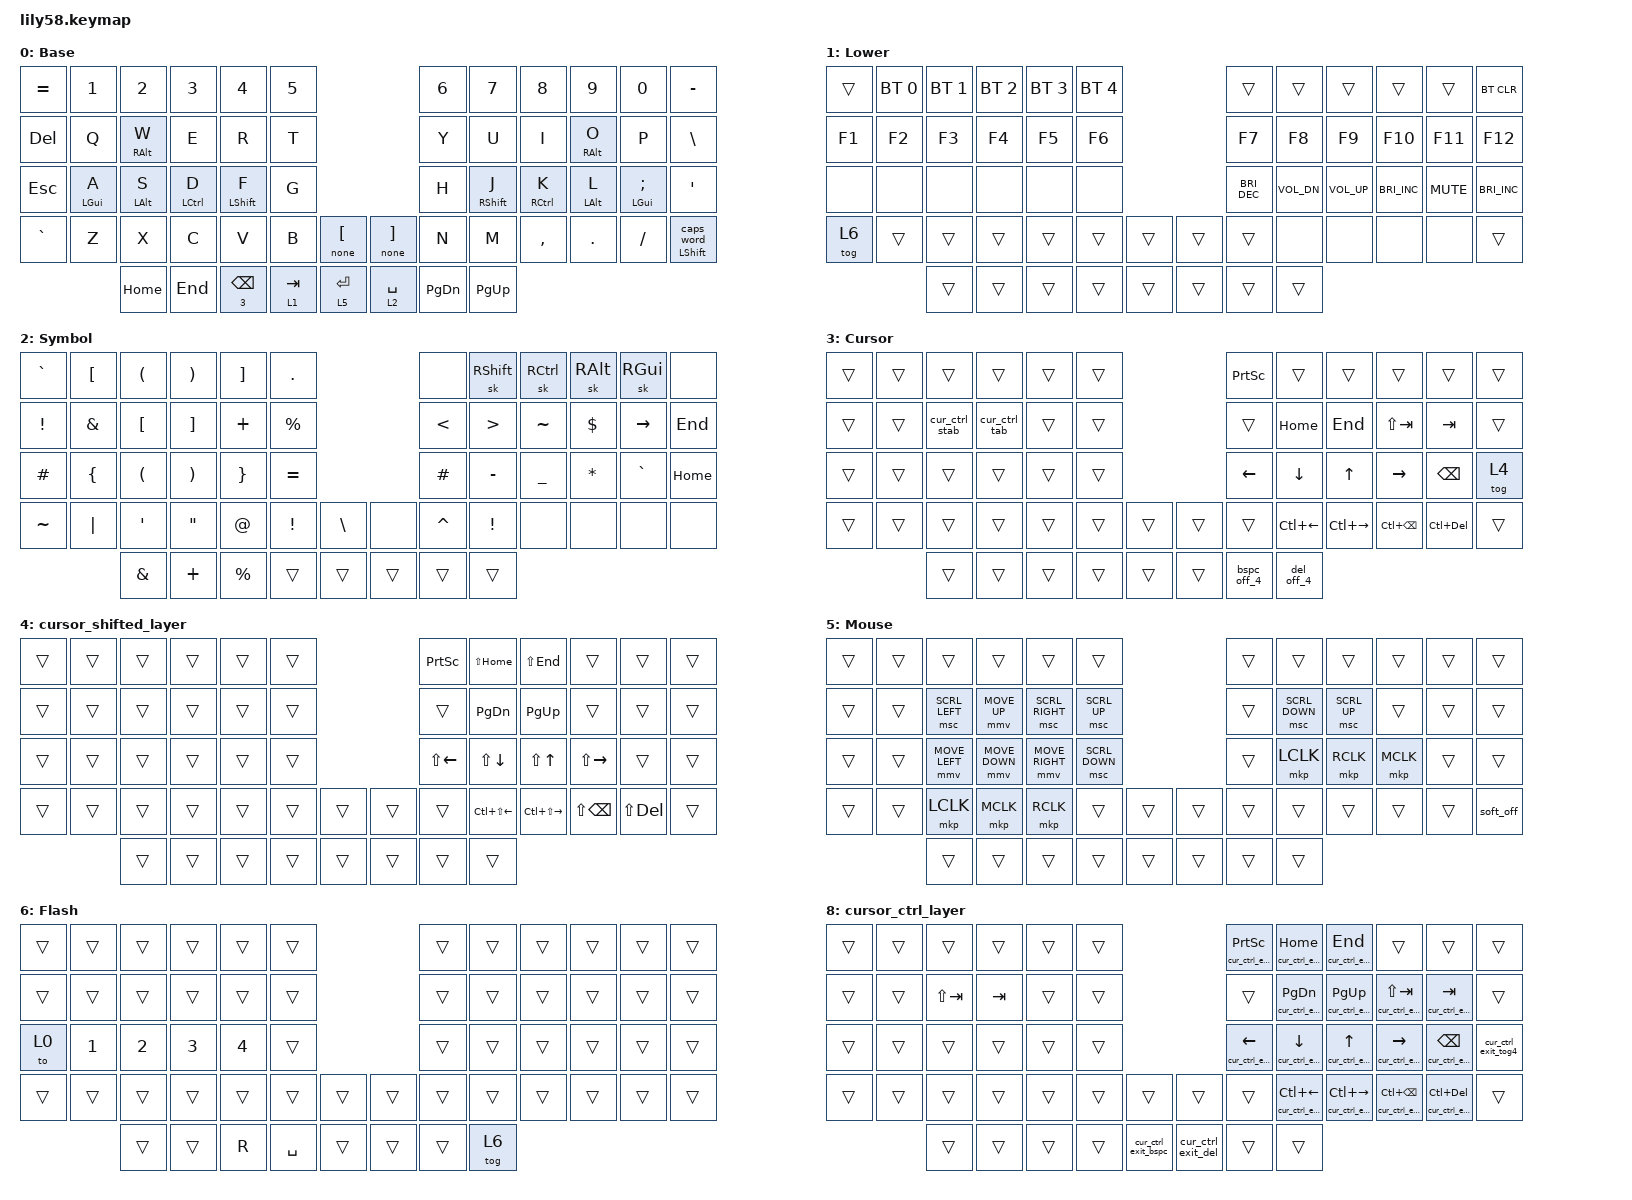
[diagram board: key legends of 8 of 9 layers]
/*
 * Copyright (c) 2020 The ZMK Contributors
 *
 * SPDX-License-Identifier: MIT
 */

#include <behaviors.dtsi>
#include <dt-bindings/zmk/keys.h>
#include <dt-bindings/zmk/bt.h>
#include <dt-bindings/zmk/ext_power.h>

#define ZMK_POINTING_DEFAULT_MOVE_VAL 2100  // default: 600
#define ZMK_POINTING_DEFAULT_SCRL_VAL 20    // default: 10
#include <dt-bindings/zmk/pointing.h>

#define LAYER_CtrlFlag 9
#define LAYER_CursorCtrl 10

/ {
    chosen {
        zmk,kscan = &sideband_scan;
    };
};

&mmv {
    x-input-code = <INPUT_REL_X>;
    y-input-code = <INPUT_REL_Y>;
    time-to-max-speed-ms = <700>;
    acceleration-exponent = <1>;
};

/ {
    macros {
        bspc_off_4: bspc_off_4 {
            compatible = "zmk,behavior-macro";
            wait-ms = <0>;
            #binding-cells = <0>;
            bindings = <&layer_off 4>, <&kp BSPC>;
        };

        del_off_4: del_off_4 {
            compatible = "zmk,behavior-macro";
            wait-ms = <0>;
            #binding-cells = <0>;
            bindings = <&layer_off 4>, <&kp DEL>;
        };

        mod_off_4: mod_off_4 {
            compatible = "zmk,behavior-macro-one-param";
            wait-ms = <0>;
            tap-ms = <0>;
            #binding-cells = <1>;
            bindings = <&macro_tap &layer_off 4>,
            <&macro_param_1to1>,
            <&macro_press &mo MACRO_PLACEHOLDER>,
            <&macro_pause_for_release>,
            <&kt_off LCTRL>,
            <&layer_off LAYER_CtrlFlag>,
            <&macro_param_1to1>,
            <&macro_release &mo MACRO_PLACEHOLDER>,
            <&macro_tap &layer_off 4>;
        };

        cur_ctrl_stab: cur_ctrl_stab {
            compatible = "zmk,behavior-macro";
            wait-ms = <0>;
            tap-ms = <0>;
            #binding-cells = <0>;
            bindings = <&kt_on LCTRL>, <&tog_on LAYER_CtrlFlag>, <&kp LS(TAB)>;
        };

        cur_ctrl_tab: cur_ctrl_tab {
            compatible = "zmk,behavior-macro";
            wait-ms = <0>;
            tap-ms = <0>;
            #binding-cells = <0>;
            bindings = <&kt_on LCTRL>, <&tog_on LAYER_CtrlFlag>, <&kp TAB>;
        };

        cur_ctrl_exit: cur_ctrl_exit {
            compatible = "zmk,behavior-macro-one-param";
            wait-ms = <0>;
            tap-ms = <0>;
            #binding-cells = <1>;
            bindings = <&kt_off LCTRL>,
                       <&layer_off LAYER_CtrlFlag>,
                       <&macro_param_1to1>,
                       <&kp MACRO_PLACEHOLDER>;
        };

        cur_ctrl_exit_tog4: cur_ctrl_exit_tog4 {
            compatible = "zmk,behavior-macro";
            wait-ms = <0>;
            #binding-cells = <0>;
            bindings = <&kt_off LCTRL>, <&layer_off LAYER_CtrlFlag>, <&tog 4>;
        };

        cur_ctrl_exit_bspc: cur_ctrl_exit_bspc {
            compatible = "zmk,behavior-macro";
            wait-ms = <0>;
            #binding-cells = <0>;
            bindings = <&kt_off LCTRL>, <&layer_off LAYER_CtrlFlag>, <&layer_off 4>, <&kp BSPC>;
        };

        cur_ctrl_exit_del: cur_ctrl_exit_del {
            compatible = "zmk,behavior-macro";
            wait-ms = <0>;
            #binding-cells = <0>;
            bindings = <&kt_off LCTRL>, <&layer_off LAYER_CtrlFlag>, <&layer_off 4>, <&kp DEL>;
        };
    };
};

/ {
    behaviors {
        capsword: capsword {
            compatible = "zmk,behavior-hold-tap";
            #binding-cells = <2>;
            tapping-term-ms = <200>;
            bindings = <&kp>, <&caps_word>;
        };

        // Left hand
        HRM_left_index: HRM_left_index {
            compatible = "zmk,behavior-hold-tap";
            #binding-cells = <2>;
            tapping-term-ms = <120>;
            bindings = <&kp>, <&kp>;
            flavor = "tap-preferred";
            quick-tap-ms = <250>;
            require-prior-idle-ms = <50>;
        };

        HRM_left_middy: HRM_left_middy {
            compatible = "zmk,behavior-hold-tap";
            #binding-cells = <2>;
            tapping-term-ms = <160>;
            bindings = <&kp>, <&kp>;
            flavor = "tap-preferred";
            quick-tap-ms = <250>;
            require-prior-idle-ms = <100>;
        };

        HRM_left_ring: HRM_left_ring {
            compatible = "zmk,behavior-hold-tap";
            #binding-cells = <2>;
            tapping-term-ms = <190>;
            bindings = <&kp>, <&kp>;
            flavor = "tap-preferred";
            quick-tap-ms = <250>;
            require-prior-idle-ms = <100>;
        };

        HRM_left_pinky: HRM_left_pinky {
            compatible = "zmk,behavior-hold-tap";
            #binding-cells = <2>;
            tapping-term-ms = <210>;
            bindings = <&kp>, <&kp>;
            flavor = "tap-preferred";
            quick-tap-ms = <250>;
            require-prior-idle-ms = <100>;
        };

        // Right hand
        HRM_right_index: HRM_right_index {
            compatible = "zmk,behavior-hold-tap";
            #binding-cells = <2>;
            tapping-term-ms = <120>;
            bindings = <&kp>, <&kp>;
            flavor = "tap-preferred";
            quick-tap-ms = <250>;
            require-prior-idle-ms = <50>;
        };

        HRM_right_middy: HRM_right_middy {
            compatible = "zmk,behavior-hold-tap";
            #binding-cells = <2>;
            tapping-term-ms = <160>;
            bindings = <&kp>, <&kp>;
            flavor = "tap-preferred";
            quick-tap-ms = <250>;
            require-prior-idle-ms = <100>;
        };

        HRM_right_ring: HRM_right_ring {
            compatible = "zmk,behavior-hold-tap";
            #binding-cells = <2>;
            tapping-term-ms = <190>;
            bindings = <&kp>, <&kp>;
            flavor = "tap-preferred";
            quick-tap-ms = <250>;
            require-prior-idle-ms = <100>;
        };

        HRM_right_pinky: HRM_right_pinky {
            compatible = "zmk,behavior-hold-tap";
            #binding-cells = <2>;
            tapping-term-ms = <210>;
            bindings = <&kp>, <&kp>;
            flavor = "tap-preferred";
            quick-tap-ms = <250>;
            require-prior-idle-ms = <100>;
        };

        bkt_tap: bkt_tap {
            compatible = "zmk,behavior-hold-tap";
            #binding-cells = <2>;
            tapping-term-ms = <1000>;
            bindings = <&none>, <&kp>;
            flavor = "tap-preferred";
        };

        space_layer: space_layer {
            compatible = "zmk,behavior-hold-tap";
            #binding-cells = <2>;
            tapping-term-ms = <150>;
            bindings = <&mo>, <&kp>;
            flavor = "balanced";
            quick-tap-ms = <100>;
            retro-tap;
        };

        thumb_layer_off_4: thumb_layer_off_4 {
            compatible = "zmk,behavior-hold-tap";
            #binding-cells = <2>;
            tapping-term-ms = <150>;
            bindings = <&mod_off_4>, <&kp>;
            flavor = "balanced";
            quick-tap-ms = <250>;
        };

        thumb_layer: thumb_layer {
            compatible = "zmk,behavior-hold-tap";
            #binding-cells = <2>;
            tapping-term-ms = <150>;
            bindings = <&mo>, <&kp>;
            flavor = "balanced";
            quick-tap-ms = <250>;
        };

        layer_off: layer_off {
            compatible = "zmk,behavior-toggle-layer";
            #binding-cells = <1>;
            display-name = "Layer Toggle Off";
            toggle-mode = "off";
        };

        kt_on: kt_on {
            compatible = "zmk,behavior-key-toggle";
            #binding-cells = <1>;
            display-name = "Key Toggle On";
            toggle-mode = "on";
        };

        kt_off: kt_off {
            compatible = "zmk,behavior-key-toggle";
            #binding-cells = <1>;
            display-name = "Key Toggle Off";
            toggle-mode = "off";
        };

        tog_on: tog_on {
            compatible = "zmk,behavior-toggle-layer";
            #binding-cells = <1>;
            display-name = "Toggle Layer On";
            toggle-mode = "on";
        };

    };
};

/ {
    conditional_layers {
        compatible = "zmk,conditional-layers";
        cursor_ctrl_cond {
            if-layers = <3 LAYER_CtrlFlag>;
            then-layer = <LAYER_CursorCtrl>;
        };
    };
};

/ {
    keymap {
        compatible = "zmk,keymap";

        default_layer {
// ------------------------------------------------------------------------------------------------------------
// | =   |  1  |  2  |  3   |  4   |  5   |                   |  6   |  7    |  8    |  9   |   0   |   -   |
// | DEL |  Q  |  W  |  E   |  R   |  T   |                   |  Y   |  U    |  I    |  O   |   P   |   \   |
// | ESC |  A  |  S  |  D   |  F   |  G   |                   |  H   |  J    |  K    |  L   |   ;   |   '   |
// | `   |  Z  |  X  |  C   |  V   |  B   |   "["  |  |  "]"  |  N   |  M    |  ,    |  .   |   /   | SHIFT |
//                     | HOME | END | BSPC |  TAB2 |  | ENTER | SPACE|  PGDN    |  PGUP    |
            display-name = "Base";
            bindings = <
                &kp EQUAL &kp N1 &kp N2 &kp N3   &kp N4   &kp N5                     &kp N6 &kp N7   &kp N8    &kp N9  &kp N0   &kp MINUS
                &kp DEL   &kp Q  &HRM_left_ring RALT W  &kp E    &kp R    &kp T                      &kp Y  &kp U    &kp I     &HRM_right_ring RALT O  &kp P    &kp BSLH
                &kp ESC   &HRM_left_pinky LGUI A &HRM_left_ring LALT S &HRM_left_middy LCTRL D &HRM_left_index LSHFT F &kp G                      &kp H  &HRM_right_index RSHFT J &HRM_right_middy RCTRL K &HRM_right_ring LALT L &HRM_right_pinky LGUI SEMI &kp SQT
                &kp GRAVE &kp Z  &kp X  &kp C    &kp V    &kp B  &bkt_tap 0 LBKT   &bkt_tap 0 RBKT &kp N  &kp M    &kp COMMA &kp DOT &kp FSLH &capsword LSHFT 0
                                &kp HOME &kp END &thumb_layer_off_4 3 BSPC &thumb_layer 1 TAB &thumb_layer 5 RET  &space_layer 2 SPACE  &kp PG_DN &kp PG_UP
            >;

            sensor-bindings = <&inc_dec_kp C_VOL_UP C_VOL_DN>;
        };

        lower_layer {
// ------------------------------------------------------------------------------------------------------------
// |       | BT1 | BT2 |  BT3 |  BT4 |  BT5 |                   |      |       |       |      |       | BTCLR |
// |  F1   |  F2 |  F3 |  F4  |  F5  |  F6  |                   |  F7  |  F8   |  F9   |  F10 |  F11  |  F12  |
// |       |     |     |      |      |      |                   |      | Mute  | VolDn | VolUp| BriDn | BriUp |
// |       |     |     |      |      |      |        |  |       |      |       |       |      |       |SFTOFF |
//                     |      |      |      |        |  |       |      |       |       |
            display-name = "Lower";
            bindings = <
&trans     &bt BT_SEL 0     &bt BT_SEL 1      &bt BT_SEL 2      &bt BT_SEL 3 &bt BT_SEL 4                 &trans    &trans    &trans    &trans    &trans    &bt BT_CLR
&kp F1     &kp F2           &kp F3            &kp F4            &kp F5       &kp F6                       &kp F7    &kp F8    &kp F9          &kp F10   &kp F11   &kp F12
&none      &none            &none             &none             &none        &none                        &kp C_BRIGHTNESS_DEC  &kp C_VOL_DN &kp C_VOL_UP  &kp C_BRIGHTNESS_INC &kp C_MUTE  &kp C_BRIGHTNESS_INC
&tog 6  &trans           &trans            &trans            &trans       &trans    &trans   &trans    &trans    &none     &none           &none     &none     &trans
                                              &trans            &trans       &trans    &trans   &trans    &trans    &trans    &trans
            >;

            sensor-bindings = <&inc_dec_kp C_VOL_UP C_VOL_DN>;
        };


        symbol_layer {
// ------------------------------------------------------------------------------------------------------------
// | `     | [   | (   |  )   |  ]   |  .   |                   |      |       |       |      |       |       |
// |  !    |  ,  |  {  |  }   |  ;   |  ?   |                   |  `   |  ←    |  ↑    |  ↓   | →     | END   |
// |   #   |  {  |  (  |  )   |  }   |  =   |                   |  #   |  -    |  _    |  *   | `     | HOME  |
// |  ~    |  <  |  |  |  -   |  >   |  /   |   \    |  |       |  '   |  DEL  |       |      |       |       |
//                     |  &   |  +   |  %   |        |  |       |      |       |       |
            display-name = "Symbol";
            bindings = <
                &kp GRAVE &kp LBKT  &kp LPAR  &kp RPAR  &kp RBKT  &kp DOT                        &none     &sk RSHFT &sk RCTRL &sk RALT   &sk RGUI  &none
                &kp EXCL  &kp AMPS  &kp LBKT  &kp RBKT  &kp PLUS  &kp PRCNT &kp LT                         &kp GT    &kp TILDE &kp DLLR  &kp RIGHT &kp END
                &kp HASH  &kp LBRC  &kp LPAR  &kp RPAR  &kp RBRC  &kp EQUAL                       &kp HASH &kp MINUS &kp UNDER  &kp STAR   &kp GRAVE &kp HOME
                &kp TILDE &kp PIPE  &kp SQT   &kp DQT   &kp AT    &kp EXCL  &kp BSLH   &none    &kp CARET &kp EXCL  &none     &none      &none     &none
                                    &kp AMPS  &kp PLUS  &kp PRCNT &trans    &trans     &trans   &trans    &trans
            >;

            sensor-bindings = <&inc_dec_kp C_VOL_UP C_VOL_DN>;
        };

        cursor_layer {
// ------------------------------------------------------------------------------------------------------------
// |       |     |     |      |      |      |                   | prnt | end   |  home |      |       |       |
// |       |     |     |      |      |      |                   |      |pgup   | pgdown|      |       |       |
// |       |     |     |      |      |      |                   |  left| down  | up    | right|tgglsh |       |
// |       |     |     |      |      |      |        |  |       |      |c-left |c-right|c-bksp|c-del  |       |
//                     |      |      |      |        |  | bckspc| del  |       |       |
            display-name = "Cursor";
            bindings = <
                &trans   &trans   &trans   &trans   &trans   &trans                      &kp PSCRN  &trans     &trans       &trans        &trans       &trans
                &trans   &trans   &cur_ctrl_stab   &cur_ctrl_tab   &trans   &trans          &trans     &kp HOME    &kp END     &kp LS(TAB)   &kp TAB      &trans
                &trans   &trans   &trans   &trans   &trans   &trans                      &kp LEFT   &kp DOWN     &kp UP        &kp RIGHT     &kp BSPC    &tog 4
                &trans   &trans   &trans   &trans   &trans   &trans   &trans   &trans    &trans     &kp LC(LEFT) &kp LC(RIGHT) &kp LC(BSPC)  &kp LC(DEL)  &trans
                                  &trans   &trans   &trans   &trans   &trans &trans &bspc_off_4 &del_off_4
            >;

            sensor-bindings = <&inc_dec_kp C_VOL_UP C_VOL_DN>;
        };

        cursor_shifted_layer {
            bindings = <
                &trans   &trans   &trans   &trans   &trans   &trans                      &kp PSCRN &kp LS(HOME) &kp LS(END) &trans        &trans       &trans
                &trans   &trans   &trans   &trans   &trans   &trans                      &trans     &kp PG_DN         &kp PG_UP           &trans        &trans       &trans
                &trans   &trans   &trans   &trans   &trans   &trans                      &kp LS(LEFT)   &kp LS(DOWN)     &kp LS(UP)        &kp LS(RIGHT)     &trans    &trans
                &trans   &trans   &trans   &trans   &trans   &trans   &trans   &trans    &trans     &kp LC(LS(LEFT)) &kp LC(LS(RIGHT)) &kp LS(BSPC)  &kp LS(DEL)  &trans
                                  &trans   &trans   &trans   &trans   &trans &trans &trans     &trans
            >;
        };


        mouse_layer {
// ------------------------------------------------------------------------------------------------------------
// |trans|trans|trans|trans |trans |trans |                   |trans |trans  |trans  |trans |trans  |trans  |
// |trans|trans|  ←  |  ↑   |  →   |trans |                   |trans |down   |up     |trans |trans  |trans  |
// |trans|trans|  ←  |  ↓   |  →   |trans |                   |trans |LCLK   |RCLK   |MCLK  |trans  |trans  |
// |trans|trans|LCLK |MCLK  |RCLK  |trans |  trans | | trans  |trans |trans  |trans  |trans |trans  |trans  |
//                     |trans|trans |trans | trans  | | trans  |trans |trans  |trans  |
            display-name = "Mouse";
            bindings = <
                &trans &trans &trans &trans &trans &trans                              &trans &trans &trans &trans &trans &trans
                &trans &trans &msc SCRL_LEFT &mmv MOVE_UP &msc SCRL_RIGHT &msc SCRL_UP       &trans &msc SCRL_DOWN &msc SCRL_UP &trans &trans &trans
                &trans &trans &mmv MOVE_LEFT &mmv MOVE_DOWN &mmv MOVE_RIGHT &msc SCRL_DOWN      &trans &mkp LCLK &mkp RCLK &mkp MCLK &trans &trans
                &trans &trans &mkp LCLK &mkp MCLK &mkp RCLK &trans &trans   &trans    &trans &trans &trans &trans &trans &soft_off
                              &trans &trans &trans &trans                              &trans &trans &trans &trans
            >;

            sensor-bindings = <&inc_dec_kp C_VOL_UP C_VOL_DN>;
        };

        flash_layer {
// ------------------------------------------------------------------------------------------------------------
// |trans|trans|trans|trans |trans |trans |                   |trans |trans  |trans  |trans |trans  |trans  |
// |trans|trans|trans|trans |trans |trans |                   |trans |trans  |trans  |trans |trans  |trans  |
// | to0 |  1  |  2  |  3   |  4   |trans |                   |trans |trans  |trans  |trans |trans  |trans  |
// |trans|trans|trans|trans |trans |trans |   trans |  | trans |trans |trans  |trans  |trans |trans  |trans  |
//                     |     |  R  |SPACE |        |  |       |      |       |  tog  |
            display-name = "Flash";
            bindings = <
                &trans &trans &trans &trans &trans &trans                      &trans &trans &trans &trans &trans &trans
                &trans &trans &trans &trans &trans &trans                      &trans &trans &trans &trans &trans &trans
                &to 0 &kp N1 &kp N2 &kp N3 &kp N4 &trans                      &trans &trans &trans &trans &trans &trans
                &trans &trans &trans &trans &trans &trans &trans &trans    &trans &trans &trans &trans &trans &trans
                              &trans &trans  &kp R &kp SPACE                  &trans &trans &trans &tog 6
            >;
        };

        extra_2 {
            status = "reserved";
        };

        extra_3 {
            status = "reserved";
        };

        ctrl_flag_layer {
            bindings = <
                &trans &trans &trans &trans &trans &trans &trans &trans &trans &trans &trans &trans
                &trans &trans &trans &trans &trans &trans &trans &trans &trans &trans &trans &trans
                &trans &trans &trans &trans &trans &trans &trans &trans &trans &trans &trans &trans &trans &trans
                &trans &trans &trans &trans &trans &trans &trans &trans
            >;
        };

        cursor_ctrl_layer {
            bindings = <
                &trans   &trans   &trans           &trans          &trans   &trans          &cur_ctrl_exit PSCRN   &cur_ctrl_exit HOME   &cur_ctrl_exit END   &trans   &trans   &trans
                &trans   &trans   &kp LS(TAB)      &kp TAB         &trans   &trans          &trans   &cur_ctrl_exit PG_DN   &cur_ctrl_exit PG_UP   &cur_ctrl_exit LS(TAB)   &cur_ctrl_exit TAB   &trans
                &trans   &trans   &trans           &trans          &trans   &trans          &cur_ctrl_exit LEFT   &cur_ctrl_exit DOWN   &cur_ctrl_exit UP   &cur_ctrl_exit RIGHT   &cur_ctrl_exit BSPC   &cur_ctrl_exit_tog4
                &trans   &trans   &trans           &trans          &trans   &trans   &trans   &trans    &trans   &cur_ctrl_exit LC(LEFT)   &cur_ctrl_exit LC(RIGHT)   &cur_ctrl_exit LC(BSPC)   &cur_ctrl_exit LC(DEL)   &trans
                                  &trans           &trans          &trans   &trans   &cur_ctrl_exit_bspc   &cur_ctrl_exit_del   &trans   &trans
            >;
        };

};
};
